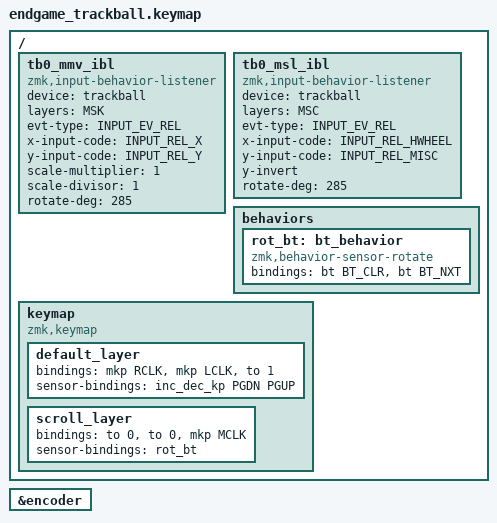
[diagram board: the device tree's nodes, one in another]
#include <dt-bindings/zmk/mouse.h>
#include <behaviors.dtsi>
#include <dt-bindings/zmk/keys.h>
#include <dt-bindings/zmk/bt.h>

#define MSK 0 // mouse key layer
#define MSC 1 // mouse scoll layer

#define INPUT_EV_REL 0x02
#define INPUT_REL_X 0x00
#define INPUT_REL_Y 0x01

&encoder {
	status = "okay";
};

/ {
        /* input config for mouse move mode on default layer (DEF & MSK) */
        tb0_mmv_ibl {
                /* new forked compatible name */
                compatible = "zmk,input-behavior-listener";
                
                /* the input point device alias */
                device = <&trackball>;

                /* only enable in default layer (DEF) & mouse key layer (MSK) */
                layers = <MSK>;

                /* event code value to override raw input event */
                /* designed for switching to mouse scroll, xy-swap, precise-mode+, etc */
                /* NOTE: only apply input-code overriding for INPUT_EV_REL */
                evt-type = <INPUT_EV_REL>;
                x-input-code = <INPUT_REL_X>;
                y-input-code = <INPUT_REL_Y>;
                scale-multiplier = <1>;
                scale-divisor = <1>;

                /* align to CCW 45 degree */
                rotate-deg = <285>;
                /* NOTE 1: This settings do not compitable with y-invert and x-invert */
                /* NOTE 2: Floating point computation requires alot of ram. */
                /*         This feature will cuase stackove flow with CONFIG_ZMK_USB_LOGGING=y */
        };
  
        /* input config for mouse scroll mode on momentary mouse scoll layer (MSC) */
        tb0_msl_ibl {
                compatible = "zmk,input-behavior-listener";
                device = <&trackball>;
                layers = <MSC>;
                evt-type = <INPUT_EV_REL>;
                
                /* slienting x-axis with alt event code */
                x-input-code = <INPUT_REL_HWHEEL>;
                y-input-code = <INPUT_REL_MISC>;

                /* invent scrolling direction */
                y-invert;

                /* align to CCW 45 degree */
                rotate-deg = <285>;
                /* NOTE 1: This settings do not compitable with y-invert and x-invert */
                /* NOTE 2: Floating point computation requires alot of ram. */
                /*         This feature will cuase stackove flow with CONFIG_ZMK_USB_LOGGING=y */
        };

	behaviors {
        	rot_bt: bt_behavior {
            		compatible = "zmk,behavior-sensor-rotate";
            		#sensor-binding-cells = <0>;
            		bindings = <&bt BT_CLR>, <&bt BT_NXT>;
        	};
    	};
	keymap {
		compatible = "zmk,keymap";

		default_layer {
			bindings = <&mkp RCLK &mkp LCLK &to 1>;
			sensor-bindings = <&inc_dec_kp PGDN PGUP>;
		};
		scroll_layer {
			bindings = <&to 0 &to 0 &mkp MCLK>;
		 	sensor-bindings	= <&rot_bt>;
 		};
	};
};
